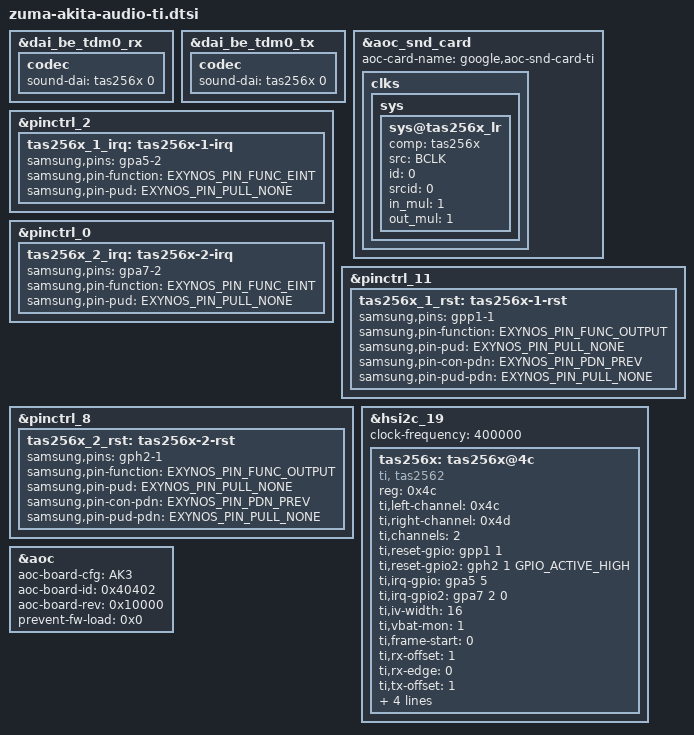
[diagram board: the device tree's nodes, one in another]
// SPDX-License-Identifier: GPL-2.0-only
/*
 * akita audio device tree source for ti amp
 *
 * Copyright 2022 Google LLC
 */

#include <dt-bindings/interrupt-controller/irq.h>
#include <dt-bindings/gpio/gpio.h>
#include <arm64/exynos/exynos-pinctrl.h>
//#include <dt-bindings/sound/google-aoc.h>

&dai_be_tdm0_rx {
	codec {
		sound-dai = <&tas256x 0>;
	};
};

&dai_be_tdm0_tx {
	codec {
		sound-dai = <&tas256x 0>;
	};
};

&aoc_snd_card {
	aoc-card-name = "google,aoc-snd-card-ti";
	clks {
		sys {
			sys@tas256x_lr {
				comp = <&tas256x>;
				src = "BCLK";
				/* clk id */
				id = <0>;
				/* clk source */
				srcid = <0>;
				/* in clk multiple */
				in_mul = <1>;
				/* out clk multiple */
				out_mul = <1>;
			};
		};
	};
};

/* GPIO_FAR_ALIVE */
&pinctrl_2 {
	tas256x_1_irq: tas256x-1-irq {
		samsung,pins = "gpa5-2"; /* XEINT_2 */
		samsung,pin-function = <EXYNOS_PIN_FUNC_EINT>;
		samsung,pin-pud = <EXYNOS_PIN_PULL_NONE>;
	};
};

/* GPIO_ALIVE */
&pinctrl_0 {
	tas256x_2_irq: tas256x-2-irq {
		samsung,pins = "gpa7-2"; /* XEINT_16 */
		samsung,pin-function = <EXYNOS_PIN_FUNC_EINT>;
		samsung,pin-pud = <EXYNOS_PIN_PULL_NONE>;
	};
};

/* GPIO_PERIC0 */
&pinctrl_11 {
	tas256x_1_rst: tas256x-1-rst {
		samsung,pins = "gpp1-1"; /* XAPC_GPIO3 */
		samsung,pin-function = <EXYNOS_PIN_FUNC_OUTPUT>;
		samsung,pin-pud = <EXYNOS_PIN_PULL_NONE>;
		samsung,pin-con-pdn = <EXYNOS_PIN_PDN_PREV>;
		samsung,pin-pud-pdn = <EXYNOS_PIN_PULL_NONE>;
	};
};

/* GPIO_PERIC1 */
&pinctrl_8 {
	tas256x_2_rst: tas256x-2-rst {
		samsung,pins = "gph2-1"; /* XHSI1_GPIO11 */
		samsung,pin-function = <EXYNOS_PIN_FUNC_OUTPUT>;
		samsung,pin-pud = <EXYNOS_PIN_PULL_NONE>;
		samsung,pin-con-pdn = <EXYNOS_PIN_PDN_PREV>;
		samsung,pin-pud-pdn = <EXYNOS_PIN_PULL_NONE>;
	};
};

&hsi2c_19 {
        #address-cells = <1>;
        #size-cells = <0>;

	status = "ok";
	clock-frequency = <400000>;

	tas256x:tas256x@4c {
		#sound-dai-cells = <1>;
		compatible = "ti, tas2562";/*or "ti,tas2564" or "ti,tas256x" */
		reg = <0x4c>;
		status = "ok";

		ti,left-channel = <0x4c>;
		ti,right-channel = <0x4d>;
		ti,channels = <2>; /* channel number */
		ti,reset-gpio = <&gpp1 1 GPIO_ACTIVE_HIGH>;
		ti,reset-gpio2 = <&gph2 1 GPIO_ACTIVE_HIGH>;
		ti,irq-gpio = <&gpa5 5 0>;
		ti,irq-gpio2 = <&gpa7 2 0>;

		ti,iv-width = <16>;
		ti,vbat-mon = <1>;
		/* frame start count on clk 0
		RX delay 1 clk fetch on clk raising
		TX delay 1 clk fetch on clk falling */
		ti,frame-start = <0>;
		ti,rx-offset = <1>;
		ti,rx-edge = <0>;
		ti,tx-offset = <1>;
		ti,tx-edge = <1>;
		ti,port_id = <0x9040>;
		pinctrl-names = "default";
		pinctrl-0 = <&tas256x_1_rst &tas256x_2_rst
				&tas256x_1_irq &tas256x_2_irq>;
	};

};

&aoc {
	aoc-board-cfg = "AK3";
	aoc-board-id = <0x40402>;
	aoc-board-rev = <0x10000>;
	prevent-fw-load = <0x0>;
};
